# QN9090 register map
Vendor: nxp.com; File version: 1.0
CPU: CM4 r0p1, little endian, MPU, no FPU, VTOR, 3 interrupt priority bits
Registers are 32-bit, read-write, reset 0x0 unless marked. A register's access mark holds for its fields unless they carry their own. Offsets are from the block's base; [hi:lo] are bit positions; {n}, {i} and the like mark numbered series; 'fields as' and 'values as' point back to an identical list.

## IOCON — I/O pin configuration (IOCON)
Base 0x4000F000
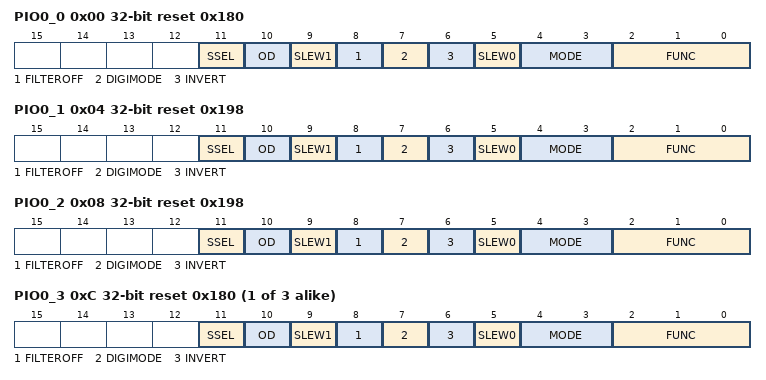
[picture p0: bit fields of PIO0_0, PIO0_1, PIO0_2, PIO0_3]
0x00 PIO0_0 reset 0x180 — Digital I/O control for port 0 pins PIO0_0
  [11] SSEL — IO Clamping Function.
    0=DISABLED (Disabled. IO clamping function disabled.); 1=ENABLED (Enabled. IO clamping function enabled.)
  [10] OD — Controls open-drain mode.
    0=NORMAL (Normal. Normal push-pull output.); 1=OPEN_DRAIN (Open-drain. Simulated open-drain output (high drive disabled).)
  [9] SLEW1 — Driver Slew Rate. This bit is used in combination with SLEW0. The higher [SLEW1,SLEW0], the quicker the slew rate.
    0=DISABLED (Disabled. Driver slew rate disabled.); 1=ENABLED (Enabled. Driver slew rate enabled.)
  [8] FILTEROFF — Control Input Glitch Filter.
    0=ENABLED (Filter enabled. Noise pulses below approximately 1 ns are filtered out.); 1=DISABLED (Filter disabled. No input filtering is done.)
  [7] DIGIMODE — Select Analog/Digital Mode.
    0=ANALOG (Analog mode.); 1=DIGITAL (Digital mode.)
  [6] INVERT — Input Polarity.
    0=DISABLED (Disabled. Input function is not inverted.); 1=ENABLED (Enabled. Input function is inverted.)
  [5] SLEW0 — Driver Slew Rate. This bit field is used in combination with SLEW1. The higher [SLEW1,SLEW0] the quicker the IO cell slew rate.
    values as SLEW1
  [4:3] MODE — Select function mode (on-chip pull-up/pull-down resistor control).
    0=PULL_UP (Pull-up. Pull-up resistor enabled.); 1=REPEATER (Repeater. Repeater mode (bus keeper).); 2=INACTIVE (Inactive. Plain Input.); 3=PULL_DOWN (Pull-down. Pull-down resistor enabled.)
  [2:0] FUNC — Select digital function assigned to this pin.
    {v}=ALT{v} (Alternative connection {v}.) (v=0..7)
0x04 PIO0_1 reset 0x198 — Digital I/O control for port 0 pins PIO0_1
  fields as PIO0_0
0x08 PIO0_2 reset 0x198 — Digital I/O control for port 0 pins PIO0_2
  fields as PIO0_0
{0x0+4i} PIO0_{i} reset 0x180 (i=3..5) — Digital I/O control for port 0 pins PIO0_{i}
  fields as PIO0_0
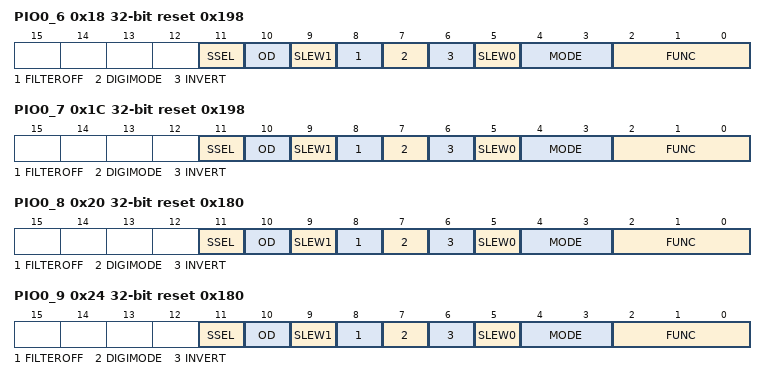
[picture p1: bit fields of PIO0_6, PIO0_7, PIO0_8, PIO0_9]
0x18 PIO0_6 reset 0x198 — Digital I/O control for port 0 pins PIO0_6
  fields as PIO0_0
0x1C PIO0_7 reset 0x198 — Digital I/O control for port 0 pins PIO0_7
  fields as PIO0_0
0x20 PIO0_8 reset 0x180 — Digital I/O control for port 0 pins PIO0_8
  fields as PIO0_0
0x24 PIO0_9 reset 0x180 — Digital I/O control for port 0 pins PIO0_9
  fields as PIO0_0
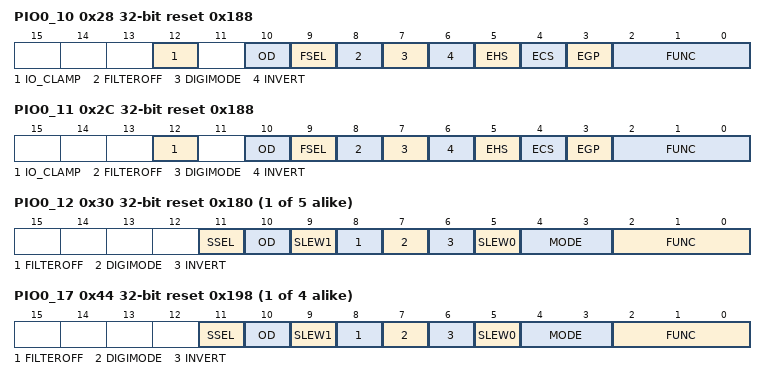
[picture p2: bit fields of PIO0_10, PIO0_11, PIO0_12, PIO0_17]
0x28 PIO0_10 reset 0x188 — Digital I/O control for port 0 pins PIO0_10
  [12] IO_CLAMP — Assert to freeze the IO. Also needs SYSCON_RETENTIONCTRL set as well. Useful in power down mode. This mode is held through power down cycle. Before releasing this mode on a wake-up, ensure the IO is set to the required direction and value by using GPIO_DIR and GPIO_PIN registers.
    values as PIO0_0.SSEL
  [10] OD — Controls open-drain mode.
    values as PIO0_0.OD
  [9] FSEL — Control Input Glitch Filter.
    0=DISABLED (Noise pulses below approximately 50 ns are filtered out.); 1=ENABLED (Noise pulses below approximately 10 ns are filtered out. If IO is in GPIO mode this control bit is irrelevant, a 3 ns filter is used.)
  [8] FILTEROFF — Control Input Glitch Filter.
    values as PIO0_0.FILTEROFF
  [7] DIGIMODE — Select Analog/Digital Mode.
    0=ANALOG (Analog mode.); 1=DIGITAL (Digital mode.)
  [6] INVERT — Input Polarity.
    values as PIO0_0.INVERT
  [5] EHS — Speed Selection. When IO is in GPIO mode set 1 for high speed GPIO, 0 for low speed GPIO. For IIC mode, this bit has no effect and the IO is always in low speed.
    0=LOW_SPEED; 1=HIGH_SPEED
  [4] ECS — Pull-up current source enable when set.
    0=DISABLED (Disabled. IO is in open drain.); 1=ENABLED (Enabled. Pull resistor is conencted.)
  [3] EGP — GPIO Mode of IO Cell.
    0=I2C_MODE (IIC mode.); 1=GPIO_MODE
  [2:0] FUNC — Select digital function assigned to this pin.
    {v}=ALT{v} (Alternative connection {v}.) (v=0..7)
0x2C PIO0_11 reset 0x188 — Digital I/O control for port 0 pins PIO0_11
  fields as PIO0_10
{0x0+4i} PIO0_{i} reset 0x180 (i=12..16) — Digital I/O control for port 0 pins PIO0_{i}
  fields as PIO0_0
{0x0+4i} PIO0_{i} reset 0x198 (i=17..20) — Digital I/O control for port 0 pins PIO0_{i}
  fields as PIO0_0
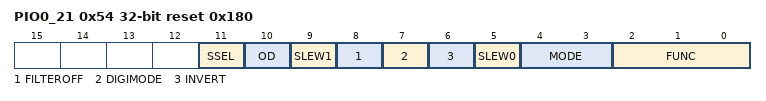
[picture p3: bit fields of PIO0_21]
0x54 PIO0_21 reset 0x180 — Digital I/O control for port 0 pins PIO0_21
  fields as PIO0_0

## Notices in the file
Copyright 2016-2019 NXP
All rights reserved.
SPDX-License-Identifier: BSD-3-Clause
